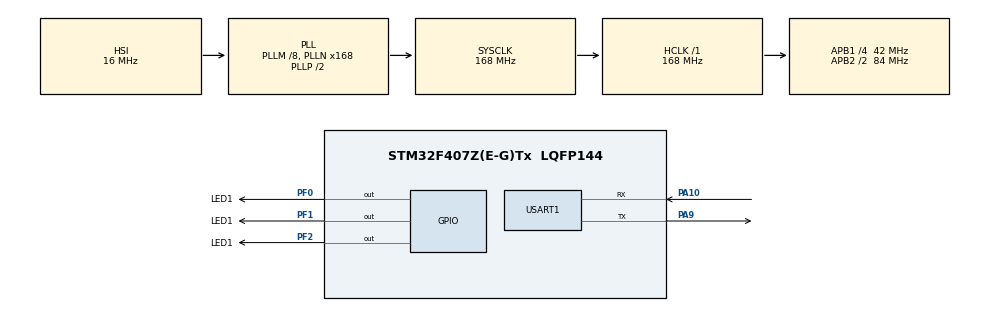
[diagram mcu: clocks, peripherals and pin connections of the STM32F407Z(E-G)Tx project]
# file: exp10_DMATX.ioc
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Dma.Request0=USART1_TX
Dma.USART1_TX.0.Direction=DMA_MEMORY_TO_PERIPH
Dma.USART1_TX.0.FIFOMode=DMA_FIFOMODE_DISABLE
Dma.USART1_TX.0.Instance=DMA2_Stream7
Dma.USART1_TX.0.MemDataAlignment=DMA_MDATAALIGN_BYTE
Dma.USART1_TX.0.MemInc=DMA_MINC_ENABLE
Dma.USART1_TX.0.Mode=DMA_CIRCULAR
Dma.USART1_TX.0.PeriphDataAlignment=DMA_PDATAALIGN_BYTE
Dma.USART1_TX.0.PeriphInc=DMA_PINC_DISABLE
Dma.USART1_TX.0.Priority=DMA_PRIORITY_HIGH
Mcu.Family=STM32F4
Mcu.Name=STM32F407Z(E-G)Tx
Mcu.Package=LQFP144
NVIC.DMA2_Stream7_IRQn=true\:0\:0\:false\:false\:true\:false\:true
NVIC.PriorityGroup=NVIC_PRIORITYGROUP_4
NVIC.USART1_IRQn=true\:0\:0\:false\:false\:true\:true\:true
PA10.Mode=Asynchronous
PA10.Signal=USART1_RX
PA9.Mode=Asynchronous
PA9.Signal=USART1_TX
PF0.GPIO_Label=LED1
PF0.PinState=GPIO_PIN_SET
PF0.Signal=GPIO_Output
PF1.GPIO_Label=LED1
PF1.PinState=GPIO_PIN_SET
PF1.Signal=GPIO_Output
PF2.GPIO_Label=LED1
PF2.PinState=GPIO_PIN_SET
PF2.Signal=GPIO_Output
PH0-OSC_IN.Mode=HSE-External-Oscillator
PH0-OSC_IN.Signal=RCC_OSC_IN
PH1-OSC_OUT.Mode=HSE-External-Oscillator
PH1-OSC_OUT.Signal=RCC_OSC_OUT
ProjectManager.HeapSize=0x200
ProjectManager.StackSize=0x400
ProjectManager.TargetToolchain=MDK-ARM V5.27
RCC.48MHZClocksFreq_Value=84000000
RCC.AHBFreq_Value=168000000
RCC.APB1CLKDivider=RCC_HCLK_DIV4
RCC.APB1Freq_Value=42000000
RCC.APB1TimFreq_Value=84000000
RCC.APB2CLKDivider=RCC_HCLK_DIV2
RCC.APB2Freq_Value=84000000
RCC.APB2TimFreq_Value=168000000
RCC.CortexFreq_Value=168000000
RCC.HCLKFreq_Value=168000000
RCC.HSE_VALUE=25000000
RCC.HSI_VALUE=16000000
RCC.LSE_VALUE=32768
RCC.PLLM=8
RCC.PLLN=168
RCC.SYSCLKFreq_VALUE=168000000
RCC.SYSCLKSource=RCC_SYSCLKSOURCE_PLLCLK
RCC.VCOOutputFreq_Value=336000000
USART1.VirtualMode=VM_ASYNC
board=custom

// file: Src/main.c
/* USER CODE BEGIN Header */
/**
  ******************************************************************************
  * @file           : main.c
  * @brief          : Main program body
  ******************************************************************************
  * @attention
  *
  * <h2><center>&copy; Copyright (c) 2022 STMicroelectronics.
  * All rights reserved.</center></h2>
  *
  * This software component is licensed by ST under BSD 3-Clause license,
  * the "License"; You may not use this file except in compliance with the
  * License. You may obtain a copy of the License at:
  *                        opensource.org/licenses/BSD-3-Clause
  *
  ******************************************************************************
  */
/* USER CODE END Header */
#include "main.h"
#include "dma.h"
#include "usart.h"
#include "gpio.h"

/* USER CODE BEGIN PD */
#define SENDBUFF_SIZE                     		10
/* USER CODE END PD */

/* USER CODE BEGIN PV */
uint8_t SendBuff[SENDBUFF_SIZE];
uint8_t aRxBuffer = 0;
/* USER CODE END PV */

void SystemClock_Config(void);

int main(void)
{
  /* USER CODE BEGIN 1 */
	uint16_t i;
	for(i=0;i<SENDBUFF_SIZE;i++)
  {
    SendBuff[i]	 = '1';

  }
  /* USER CODE END 1 */

  /* MCU Configuration--------------------------------------------------------*/

  /* Reset of all peripherals, Initializes the Flash interface and the Systick. */
  HAL_Init();

  /* Configure the system clock */
  SystemClock_Config();

  /* Initialize all configured peripherals */
  MX_GPIO_Init();
  MX_DMA_Init();
  MX_USART1_UART_Init();
  /* USER CODE BEGIN 2 */
	HAL_UART_Receive_IT(&huart1, &aRxBuffer, 1);

	HAL_UART_Transmit_DMA(&huart1, (uint8_t *)SendBuff ,SENDBUFF_SIZE);
  /* USER CODE END 2 */

  /* Infinite loop */
  while (1)
  {
		HAL_GPIO_WritePin(LED1F1_GPIO_Port, LED1F1_Pin, GPIO_PIN_RESET);
		HAL_Delay(500);
		HAL_GPIO_WritePin(LED1F1_GPIO_Port, LED1F1_Pin, GPIO_PIN_SET);
		HAL_Delay(500);
  }
}

void SystemClock_Config(void)
{
  RCC_OscInitTypeDef RCC_OscInitStruct = {0};
  RCC_ClkInitTypeDef RCC_ClkInitStruct = {0};

  /** Configure the main internal regulator output voltage
  */
  __HAL_RCC_PWR_CLK_ENABLE();
  __HAL_PWR_VOLTAGESCALING_CONFIG(PWR_REGULATOR_VOLTAGE_SCALE1);
  /** Initializes the RCC Oscillators according to the specified parameters
  * in the RCC_OscInitTypeDef structure.
  */
  RCC_OscInitStruct.OscillatorType = RCC_OSCILLATORTYPE_HSI;
  RCC_OscInitStruct.HSIState = RCC_HSI_ON;
  RCC_OscInitStruct.HSICalibrationValue = RCC_HSICALIBRATION_DEFAULT;
  RCC_OscInitStruct.PLL.PLLState = RCC_PLL_ON;
  RCC_OscInitStruct.PLL.PLLSource = RCC_PLLSOURCE_HSI;
  RCC_OscInitStruct.PLL.PLLM = 8;
  RCC_OscInitStruct.PLL.PLLN = 168;
  RCC_OscInitStruct.PLL.PLLP = RCC_PLLP_DIV2;
  RCC_OscInitStruct.PLL.PLLQ = 4;
  if (HAL_RCC_OscConfig(&RCC_OscInitStruct) != HAL_OK)
  {
    Error_Handler();
  }
  /** Initializes the CPU, AHB and APB buses clocks
  */
  RCC_ClkInitStruct.ClockType = RCC_CLOCKTYPE_HCLK|RCC_CLOCKTYPE_SYSCLK
                              |RCC_CLOCKTYPE_PCLK1|RCC_CLOCKTYPE_PCLK2;
  RCC_ClkInitStruct.SYSCLKSource = RCC_SYSCLKSOURCE_PLLCLK;
  RCC_ClkInitStruct.AHBCLKDivider = RCC_SYSCLK_DIV1;
  RCC_ClkInitStruct.APB1CLKDivider = RCC_HCLK_DIV4;
  RCC_ClkInitStruct.APB2CLKDivider = RCC_HCLK_DIV2;

  if (HAL_RCC_ClockConfig(&RCC_ClkInitStruct, FLASH_LATENCY_5) != HAL_OK)
  {
    Error_Handler();
  }
}

/* USER CODE BEGIN 4 */
void HAL_UART_RxCpltCallback(UART_HandleTypeDef *huart)
{
	HAL_UART_Transmit(&huart1, &aRxBuffer, 1, 0);
	HAL_UART_Receive_IT(&huart1, &aRxBuffer, 1);
}
/* USER CODE END 4 */

void Error_Handler(void)
{
  __disable_irq();
  while (1)
  {
  }
}

/************************ (C) COPYRIGHT STMicroelectronics *****END OF FILE****/
